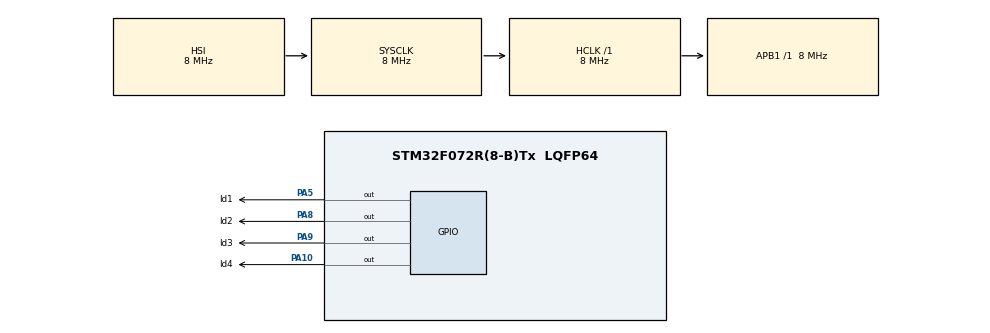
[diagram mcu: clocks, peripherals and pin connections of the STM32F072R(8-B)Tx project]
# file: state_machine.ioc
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Mcu.Family=STM32F0
Mcu.Name=STM32F072R(8-B)Tx
Mcu.Package=LQFP64
NVIC.TIM1_BRK_UP_TRG_COM_IRQn=true\:0\:0\:false\:false\:true\:true\:true\:true
PA10.GPIO_Label=ld4
PA10.GPIO_Speed=GPIO_SPEED_FREQ_MEDIUM
PA10.Signal=GPIO_Output
PA13.Mode=Serial_Wire
PA13.Signal=SYS_SWDIO
PA14.Mode=Serial_Wire
PA14.Signal=SYS_SWCLK
PA5.GPIO_Label=ld1
PA5.GPIO_Speed=GPIO_SPEED_FREQ_MEDIUM
PA5.Signal=GPIO_Output
PA8.GPIO_Label=ld2
PA8.GPIO_Speed=GPIO_SPEED_FREQ_MEDIUM
PA8.Signal=GPIO_Output
PA9.GPIO_Label=ld3
PA9.GPIO_Speed=GPIO_SPEED_FREQ_MEDIUM
PA9.Signal=GPIO_Output
PF0-OSC_IN.Mode=HSE-External-Oscillator
PF0-OSC_IN.Signal=RCC_OSC_IN
PF1-OSC_OUT.Mode=HSE-External-Oscillator
PF1-OSC_OUT.Signal=RCC_OSC_OUT
ProjectManager.HeapSize=0x200
ProjectManager.StackSize=0x400
ProjectManager.TargetToolchain=STM32CubeIDE
RCC.AHBFreq_Value=8000000
RCC.APB1Freq_Value=8000000
RCC.APB1TimFreq_Value=8000000
RCC.FLatency-AdvancedSettings=FLASH_LATENCY_0
RCC.HCLKFreq_Value=8000000
RCC.PLLDivider=RCC_PREDIV_DIV2
RCC.PLLMUL=RCC_PLL_MUL12
RCC.PREFETCH_ENABLE-AdvancedSettings=1
RCC.SYSCLKFreq_VALUE=8000000
TIM1.Period=999
TIM1.Prescaler=7999
VP_TIM1_VS_ClockSourceINT.Mode=Internal
board=NUCLEO-F072RB

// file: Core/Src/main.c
/* USER CODE BEGIN Header */
/**
  ******************************************************************************
  * @file           : main.c
  * @brief          : Main program body
  ******************************************************************************
  * @attention
  *
  * Copyright (c) 2024 STMicroelectronics.
  * All rights reserved.
  *
  * This software is licensed under terms that can be found in the LICENSE file
  * in the root directory of this software component.
  * If no LICENSE file comes with this software, it is provided AS-IS.
  *
  ******************************************************************************
  */
/* USER CODE END Header */
#include "main.h"

/* USER CODE BEGIN Includes */
#include "statemachine.h"
/* USER CODE END Includes */

/* USER CODE BEGIN PTD */
int clockCount=0;
extern state_Type current_state;
extern void (*state_table[])(void);
/* USER CODE END PTD */

TIM_HandleTypeDef htim1;

void SystemClock_Config(void);
static void MX_GPIO_Init(void);
static void MX_TIM1_Init(void);

int main(void)
{

  /* MCU Configuration--------------------------------------------------------*/

  /* Reset of all peripherals, Initializes the Flash interface and the Systick. */
  HAL_Init();

  /* Configure the system clock */
  SystemClock_Config();

  /* Initialize all configured peripherals */
  MX_GPIO_Init();
  MX_TIM1_Init();
  /* USER CODE BEGIN 2 */
HAL_TIM_Base_Start_IT(&htim1);
stateMachine_init(); // bizim ilk current_state imiizi belirler yani ld1 den başlar
  /* USER CODE END 2 */

  /* Infinite loop */
  while (1)
  {

    /* USER CODE BEGIN 3 */

//	  HAL_GPIO_WritePin(GPIOA , ld1_Pin , 1) ;
//	  HAL_GPIO_WritePin(GPIOA , ld2_Pin , 1) ;
//	  HAL_GPIO_WritePin(GPIOA , ld3_Pin , 1) ;
//	  HAL_GPIO_WritePin(GPIOA , ld4_Pin , 1) ;

	  state_table[current_state]();

  }
  /* USER CODE END 3 */
}

void SystemClock_Config(void)
{
  RCC_OscInitTypeDef RCC_OscInitStruct = {0};
  RCC_ClkInitTypeDef RCC_ClkInitStruct = {0};

  /** Initializes the RCC Oscillators according to the specified parameters
  * in the RCC_OscInitTypeDef structure.
  */
  RCC_OscInitStruct.OscillatorType = RCC_OSCILLATORTYPE_HSI;
  RCC_OscInitStruct.HSIState = RCC_HSI_ON;
  RCC_OscInitStruct.HSICalibrationValue = RCC_HSICALIBRATION_DEFAULT;
  RCC_OscInitStruct.PLL.PLLState = RCC_PLL_NONE;
  if (HAL_RCC_OscConfig(&RCC_OscInitStruct) != HAL_OK)
  {
    Error_Handler();
  }

  /** Initializes the CPU, AHB and APB buses clocks
  */
  RCC_ClkInitStruct.ClockType = RCC_CLOCKTYPE_HCLK|RCC_CLOCKTYPE_SYSCLK
                              |RCC_CLOCKTYPE_PCLK1;
  RCC_ClkInitStruct.SYSCLKSource = RCC_SYSCLKSOURCE_HSI;
  RCC_ClkInitStruct.AHBCLKDivider = RCC_SYSCLK_DIV1;
  RCC_ClkInitStruct.APB1CLKDivider = RCC_HCLK_DIV1;

  if (HAL_RCC_ClockConfig(&RCC_ClkInitStruct, FLASH_LATENCY_0) != HAL_OK)
  {
    Error_Handler();
  }
}

static void MX_TIM1_Init(void)
{

  TIM_ClockConfigTypeDef sClockSourceConfig = {0};
  TIM_MasterConfigTypeDef sMasterConfig = {0};

  htim1.Instance = TIM1;
  htim1.Init.Prescaler = 7999;
  htim1.Init.CounterMode = TIM_COUNTERMODE_UP;
  htim1.Init.Period = 999;
  htim1.Init.ClockDivision = TIM_CLOCKDIVISION_DIV1;
  htim1.Init.RepetitionCounter = 0;
  htim1.Init.AutoReloadPreload = TIM_AUTORELOAD_PRELOAD_DISABLE;
  if (HAL_TIM_Base_Init(&htim1) != HAL_OK)
  {
    Error_Handler();
  }
  sClockSourceConfig.ClockSource = TIM_CLOCKSOURCE_INTERNAL;
  if (HAL_TIM_ConfigClockSource(&htim1, &sClockSourceConfig) != HAL_OK)
  {
    Error_Handler();
  }
  sMasterConfig.MasterOutputTrigger = TIM_TRGO_RESET;
  sMasterConfig.MasterSlaveMode = TIM_MASTERSLAVEMODE_DISABLE;
  if (HAL_TIMEx_MasterConfigSynchronization(&htim1, &sMasterConfig) != HAL_OK)
  {
    Error_Handler();
  }

}

static void MX_GPIO_Init(void)
{
  GPIO_InitTypeDef GPIO_InitStruct = {0};

  /* GPIO Ports Clock Enable */
  __HAL_RCC_GPIOF_CLK_ENABLE();
  __HAL_RCC_GPIOA_CLK_ENABLE();

  /*Configure GPIO pin Output Level */
  HAL_GPIO_WritePin(GPIOA, ld1_Pin|ld2_Pin|ld3_Pin|ld4_Pin, GPIO_PIN_RESET);

  /*Configure GPIO pins : ld1_Pin ld2_Pin ld3_Pin ld4_Pin */
  GPIO_InitStruct.Pin = ld1_Pin|ld2_Pin|ld3_Pin|ld4_Pin;
  GPIO_InitStruct.Mode = GPIO_MODE_OUTPUT_PP;
  GPIO_InitStruct.Pull = GPIO_NOPULL;
  GPIO_InitStruct.Speed = GPIO_SPEED_FREQ_MEDIUM;
  HAL_GPIO_Init(GPIOA, &GPIO_InitStruct);

}

/* USER CODE BEGIN 4 */
void HAL_TIM_PeriodElapsedCallback(TIM_HandleTypeDef *htim)
{
	clockCount++;

}
/* USER CODE END 4 */

void Error_Handler(void)
{
  __disable_irq();
  while (1)
  {
  }
}
